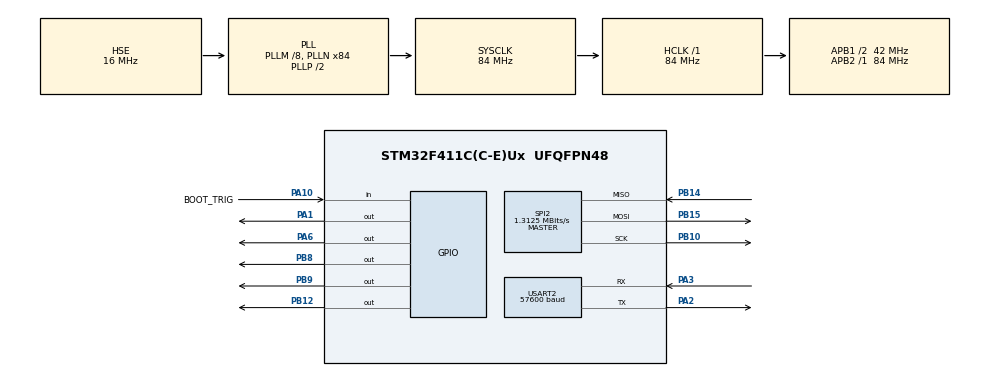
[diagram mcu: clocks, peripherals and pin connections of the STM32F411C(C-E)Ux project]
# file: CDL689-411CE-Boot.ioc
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Mcu.Family=STM32F4
Mcu.Name=STM32F411C(C-E)Ux
Mcu.Package=UFQFPN48
NVIC.PriorityGroup=NVIC_PRIORITYGROUP_4
NVIC.SPI2_IRQn=true\:0\:0\:false\:false\:true\:true\:true
NVIC.TIM1_UP_TIM10_IRQn=true\:0\:0\:false\:false\:true\:false\:true
NVIC.TIM2_IRQn=true\:1\:0\:true\:false\:true\:true\:true
NVIC.TimeBase=TIM1_UP_TIM10_IRQn
NVIC.TimeBaseIP=TIM1
NVIC.USART2_IRQn=true\:5\:0\:true\:false\:true\:true\:true
PA1.Signal=GPIO_Output
PA10.GPIO_Label=BOOT_TRIG
PA10.GPIO_PuPd=GPIO_PULLUP
PA10.Signal=GPIO_Input
PA2.Mode=Asynchronous
PA2.Signal=USART2_TX
PA3.Mode=Asynchronous
PA3.Signal=USART2_RX
PA6.Signal=GPIO_Output
PB10.Mode=Full_Duplex_Master
PB10.Signal=SPI2_SCK
PB12.PinState=GPIO_PIN_SET
PB12.Signal=GPIO_Output
PB14.Mode=Full_Duplex_Master
PB14.Signal=SPI2_MISO
PB15.Mode=Full_Duplex_Master
PB15.Signal=SPI2_MOSI
PB8.Signal=GPIO_Output
PB9.Signal=GPIO_Output
PH0\ -\ OSC_IN.Mode=HSE-External-Oscillator
PH0\ -\ OSC_IN.Signal=RCC_OSC_IN
PH1\ -\ OSC_OUT.Mode=HSE-External-Oscillator
PH1\ -\ OSC_OUT.Signal=RCC_OSC_OUT
ProjectManager.HeapSize=0x200
ProjectManager.StackSize=0x400
ProjectManager.TargetToolchain=STM32CubeIDE
RCC.48MHZClocksFreq_Value=42000000
RCC.AHBFreq_Value=84000000
RCC.APB1CLKDivider=RCC_HCLK_DIV2
RCC.APB1Freq_Value=42000000
RCC.APB1TimFreq_Value=84000000
RCC.APB2Freq_Value=84000000
RCC.APB2TimFreq_Value=84000000
RCC.CortexFreq_Value=84000000
RCC.HCLKFreq_Value=84000000
RCC.HSE_VALUE=16000000
RCC.HSI_VALUE=16000000
RCC.LSE_VALUE=32768
RCC.PLLM=8
RCC.PLLN=84
RCC.PLLSourceVirtual=RCC_PLLSOURCE_HSE
RCC.SYSCLKFreq_VALUE=84000000
RCC.SYSCLKSource=RCC_SYSCLKSOURCE_PLLCLK
RCC.VCOOutputFreq_Value=168000000
SPI2.BaudRatePrescaler=SPI_BAUDRATEPRESCALER_32
SPI2.CLKPhase=SPI_PHASE_2EDGE
SPI2.CLKPolarity=SPI_POLARITY_HIGH
SPI2.CalculateBaudRate=1.3125 MBits/s
SPI2.Direction=SPI_DIRECTION_2LINES
SPI2.Mode=SPI_MODE_MASTER
SPI2.VirtualType=VM_MASTER
TIM2.AutoReloadPreload=TIM_AUTORELOAD_PRELOAD_ENABLE
TIM2.Period=10000
TIM2.Prescaler=84
USART2.BaudRate=57600
USART2.OverSampling=UART_OVERSAMPLING_8
USART2.VirtualMode=VM_ASYNC
VP_SYS_VS_tim1.Mode=TIM1
VP_TIM2_VS_ClockSourceINT.Mode=Internal
board=custom

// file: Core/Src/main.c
/* USER CODE BEGIN Header */
/**
  ******************************************************************************
  * @file           : main.c
  * @brief          : Main program body
  ******************************************************************************
  * @attention
  *
  * <h2><center>&copy; Copyright (c) 2022 STMicroelectronics.
  * All rights reserved.</center></h2>
  *
  * This software component is licensed by ST under Ultimate Liberty license
  * SLA0044, the "License"; You may not use this file except in compliance with
  * the License. You may obtain a copy of the License at:
  *                             www.st.com/SLA0044
  *
  ******************************************************************************
  */
/* USER CODE END Header */
#include "main.h"

/* USER CODE BEGIN Includes */
#include "blt_conf.h"
#include "app.h"
/* USER CODE END Includes */

SPI_HandleTypeDef hspi2;

TIM_HandleTypeDef htim2;

void SystemClock_Config(void);
static void MX_GPIO_Init(void);
static void MX_SPI2_Init(void);
static void MX_USART2_UART_Init(void);
static void MX_TIM2_Init(void);

int main(void)
{

  /* MCU Configuration--------------------------------------------------------*/

  /* Reset of all peripherals, Initializes the Flash interface and the Systick. */
  HAL_Init();

  /* Configure the system clock */
  SystemClock_Config();

  /* Initialize all configured peripherals */
  MX_GPIO_Init();
  MX_SPI2_Init();
  MX_USART2_UART_Init();
  MX_TIM2_Init();
  /* USER CODE BEGIN 2 */
  /* Initialize the bootloader application. */

  AppInit();

  /* USER CODE END 2 */

  /* Infinite loop */
  /* USER CODE BEGIN WHILE */
  while (1)
  {
	  //HAL_IWDG_Refresh(&hiwdg);
	  AppTask();

    /* USER CODE END WHILE */

  }
}

void SystemClock_Config(void)
{
  RCC_OscInitTypeDef RCC_OscInitStruct = {0};
  RCC_ClkInitTypeDef RCC_ClkInitStruct = {0};

  /** Configure the main internal regulator output voltage
  */
  __HAL_RCC_PWR_CLK_ENABLE();
  __HAL_PWR_VOLTAGESCALING_CONFIG(PWR_REGULATOR_VOLTAGE_SCALE1);
  /** Initializes the RCC Oscillators according to the specified parameters
  * in the RCC_OscInitTypeDef structure.
  */
  RCC_OscInitStruct.OscillatorType = RCC_OSCILLATORTYPE_HSE;
  RCC_OscInitStruct.HSEState = RCC_HSE_ON;
  RCC_OscInitStruct.PLL.PLLState = RCC_PLL_ON;
  RCC_OscInitStruct.PLL.PLLSource = RCC_PLLSOURCE_HSE;
  RCC_OscInitStruct.PLL.PLLM = 8;
  RCC_OscInitStruct.PLL.PLLN = 84;
  RCC_OscInitStruct.PLL.PLLP = RCC_PLLP_DIV2;
  RCC_OscInitStruct.PLL.PLLQ = 4;
  if (HAL_RCC_OscConfig(&RCC_OscInitStruct) != HAL_OK)
  {
    Error_Handler();
  }
  /** Initializes the CPU, AHB and APB buses clocks
  */
  RCC_ClkInitStruct.ClockType = RCC_CLOCKTYPE_HCLK|RCC_CLOCKTYPE_SYSCLK
                              |RCC_CLOCKTYPE_PCLK1|RCC_CLOCKTYPE_PCLK2;
  RCC_ClkInitStruct.SYSCLKSource = RCC_SYSCLKSOURCE_PLLCLK;
  RCC_ClkInitStruct.AHBCLKDivider = RCC_SYSCLK_DIV1;
  RCC_ClkInitStruct.APB1CLKDivider = RCC_HCLK_DIV2;
  RCC_ClkInitStruct.APB2CLKDivider = RCC_HCLK_DIV1;

  if (HAL_RCC_ClockConfig(&RCC_ClkInitStruct, FLASH_LATENCY_2) != HAL_OK)
  {
    Error_Handler();
  }
}

static void MX_SPI2_Init(void)
{

  /* SPI2 parameter configuration*/
  hspi2.Instance = SPI2;
  hspi2.Init.Mode = SPI_MODE_MASTER;
  hspi2.Init.Direction = SPI_DIRECTION_2LINES;
  hspi2.Init.DataSize = SPI_DATASIZE_8BIT;
  hspi2.Init.CLKPolarity = SPI_POLARITY_HIGH;
  hspi2.Init.CLKPhase = SPI_PHASE_2EDGE;
  hspi2.Init.NSS = SPI_NSS_SOFT;
  hspi2.Init.BaudRatePrescaler = SPI_BAUDRATEPRESCALER_32;
  hspi2.Init.FirstBit = SPI_FIRSTBIT_MSB;
  hspi2.Init.TIMode = SPI_TIMODE_DISABLE;
  hspi2.Init.CRCCalculation = SPI_CRCCALCULATION_DISABLE;
  hspi2.Init.CRCPolynomial = 10;
  if (HAL_SPI_Init(&hspi2) != HAL_OK)
  {
    Error_Handler();
  }

}

static void MX_TIM2_Init(void)
{

  TIM_ClockConfigTypeDef sClockSourceConfig = {0};
  TIM_MasterConfigTypeDef sMasterConfig = {0};

  htim2.Instance = TIM2;
  htim2.Init.Prescaler = 84;
  htim2.Init.CounterMode = TIM_COUNTERMODE_UP;
  htim2.Init.Period = 10000;
  htim2.Init.ClockDivision = TIM_CLOCKDIVISION_DIV1;
  htim2.Init.AutoReloadPreload = TIM_AUTORELOAD_PRELOAD_ENABLE;
  if (HAL_TIM_Base_Init(&htim2) != HAL_OK)
  {
    Error_Handler();
  }
  sClockSourceConfig.ClockSource = TIM_CLOCKSOURCE_INTERNAL;
  if (HAL_TIM_ConfigClockSource(&htim2, &sClockSourceConfig) != HAL_OK)
  {
    Error_Handler();
  }
  sMasterConfig.MasterOutputTrigger = TIM_TRGO_RESET;
  sMasterConfig.MasterSlaveMode = TIM_MASTERSLAVEMODE_DISABLE;
  if (HAL_TIMEx_MasterConfigSynchronization(&htim2, &sMasterConfig) != HAL_OK)
  {
    Error_Handler();
  }

}

static void MX_USART2_UART_Init(void)
{

  LL_USART_InitTypeDef USART_InitStruct = {0};

  LL_GPIO_InitTypeDef GPIO_InitStruct = {0};

  /* Peripheral clock enable */
  LL_APB1_GRP1_EnableClock(LL_APB1_GRP1_PERIPH_USART2);

  LL_AHB1_GRP1_EnableClock(LL_AHB1_GRP1_PERIPH_GPIOA);
  /**USART2 GPIO Configuration
  PA2   ------> USART2_TX
  PA3   ------> USART2_RX
  */
  GPIO_InitStruct.Pin = LL_GPIO_PIN_2|LL_GPIO_PIN_3;
  GPIO_InitStruct.Mode = LL_GPIO_MODE_ALTERNATE;
  GPIO_InitStruct.Speed = LL_GPIO_SPEED_FREQ_VERY_HIGH;
  GPIO_InitStruct.OutputType = LL_GPIO_OUTPUT_PUSHPULL;
  GPIO_InitStruct.Pull = LL_GPIO_PULL_NO;
  GPIO_InitStruct.Alternate = LL_GPIO_AF_7;
  LL_GPIO_Init(GPIOA, &GPIO_InitStruct);

  /* USART2 interrupt Init */
  NVIC_SetPriority(USART2_IRQn, NVIC_EncodePriority(NVIC_GetPriorityGrouping(),5, 0));
  NVIC_EnableIRQ(USART2_IRQn);

  USART_InitStruct.BaudRate = 57600;
  USART_InitStruct.DataWidth = LL_USART_DATAWIDTH_8B;
  USART_InitStruct.StopBits = LL_USART_STOPBITS_1;
  USART_InitStruct.Parity = LL_USART_PARITY_NONE;
  USART_InitStruct.TransferDirection = LL_USART_DIRECTION_TX_RX;
  USART_InitStruct.HardwareFlowControl = LL_USART_HWCONTROL_NONE;
  USART_InitStruct.OverSampling = LL_USART_OVERSAMPLING_8;
  LL_USART_Init(USART2, &USART_InitStruct);
  LL_USART_ConfigAsyncMode(USART2);
  LL_USART_Enable(USART2);

}

static void MX_GPIO_Init(void)
{
  GPIO_InitTypeDef GPIO_InitStruct = {0};

  /* GPIO Ports Clock Enable */
  __HAL_RCC_GPIOH_CLK_ENABLE();
  __HAL_RCC_GPIOA_CLK_ENABLE();
  __HAL_RCC_GPIOB_CLK_ENABLE();

  /*Configure GPIO pin Output Level */
  HAL_GPIO_WritePin(GPIOA, GPIO_PIN_1|GPIO_PIN_6, GPIO_PIN_RESET);

  /*Configure GPIO pin Output Level */
  HAL_GPIO_WritePin(GPIOB, GPIO_PIN_12, GPIO_PIN_SET);

  /*Configure GPIO pin Output Level */
  HAL_GPIO_WritePin(GPIOB, GPIO_PIN_8|GPIO_PIN_9, GPIO_PIN_RESET);

  /*Configure GPIO pins : PA1 PA6 */
  GPIO_InitStruct.Pin = GPIO_PIN_1|GPIO_PIN_6;
  GPIO_InitStruct.Mode = GPIO_MODE_OUTPUT_PP;
  GPIO_InitStruct.Pull = GPIO_NOPULL;
  GPIO_InitStruct.Speed = GPIO_SPEED_FREQ_LOW;
  HAL_GPIO_Init(GPIOA, &GPIO_InitStruct);

  /*Configure GPIO pins : PB12 PB8 PB9 */
  GPIO_InitStruct.Pin = GPIO_PIN_12|GPIO_PIN_8|GPIO_PIN_9;
  GPIO_InitStruct.Mode = GPIO_MODE_OUTPUT_PP;
  GPIO_InitStruct.Pull = GPIO_NOPULL;
  GPIO_InitStruct.Speed = GPIO_SPEED_FREQ_LOW;
  HAL_GPIO_Init(GPIOB, &GPIO_InitStruct);

  /*Configure GPIO pin : BOOT_TRIG_Pin */
  GPIO_InitStruct.Pin = BOOT_TRIG_Pin;
  GPIO_InitStruct.Mode = GPIO_MODE_INPUT;
  GPIO_InitStruct.Pull = GPIO_PULLUP;
  HAL_GPIO_Init(BOOT_TRIG_GPIO_Port, &GPIO_InitStruct);

}

void HAL_TIM_PeriodElapsedCallback(TIM_HandleTypeDef *htim)
{
  if (htim->Instance == TIM1) {
    HAL_IncTick();
  }
}

void Error_Handler(void)
{
}

/************************ (C) COPYRIGHT STMicroelectronics *****END OF FILE****/
